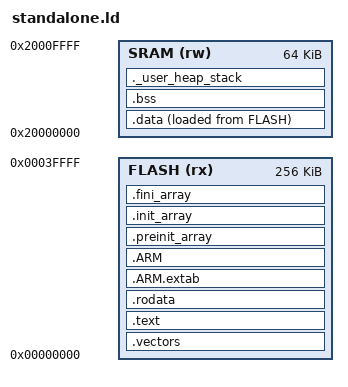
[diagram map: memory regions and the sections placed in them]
/*
******************************************************************************
**
**  File        : LinkerScript.ld
**
**  Author      : STM32CubeIDE
**
**  Abstract    : Linker script for STM32H7 series
**                2048Kbytes FLASH and 1056Kbytes RAM
**
**                Set heap size, stack size and stack location according
**                to application requirements.
**
**                Set memory bank area and size if external memory is used.
**
**  Target      : STMicroelectronics STM32
**
**  Distribution: The file is distributed as is, without any warranty
**                of any kind.
**
*****************************************************************************
** @attention
**
** <h2><center>&copy; Copyright (c) 2021 STMicroelectronics.
** All rights reserved.</center></h2>
**
** This software component is licensed by ST under BSD 3-Clause license,
** the "License"; You may not use this file except in compliance with the
** License. You may obtain a copy of the License at:
**                        opensource.org/licenses/BSD-3-Clause
**
****************************************************************************
*/

/* Highest address of the user mode stack */
_estack = ORIGIN(SRAM) + LENGTH(SRAM);    /* end of RAM */
/* Generate a link error if heap and stack don't fit into RAM */
_Min_Heap_Size = 0x4000 ;      /* required amount of heap  */
_Min_Stack_Size = 0x1000 ; /* required amount of stack */

MEMORY
{
    FLASH (rx) : ORIGIN = 0x00000000, LENGTH = 256K
    SRAM (rw) : ORIGIN = 0x20000000, LENGTH = 64K
}

ENTRY(Reset_Handler)

/* Define output sections */
SECTIONS
{
    /* The startup code goes first into FLASH */
    .vectors :
    {
        . = ALIGN(4);
        KEEP(*(.vectors)) /* Startup code */
        . = ALIGN(4);
    } >FLASH

    /* The program code and other data goes into FLASH */
    .text :
    {
        . = ALIGN(4);
        *(.text)           /* .text sections (code) */
        *(.text*)          /* .text* sections (code) */
        *(.glue_7)         /* glue arm to thumb code */
        *(.glue_7t)        /* glue thumb to arm code */
        *(.eh_frame)

        KEEP (*(.init))
        KEEP (*(.fini))

        . = ALIGN(4);
        __etext = .;        /* define a global symbols at end of code */
    } >FLASH

    /* Constant data goes into FLASH */
    .rodata :
    {
        . = ALIGN(4);
        *(.rodata)         /* .rodata sections (constants, strings, etc.) */
        *(.rodata*)        /* .rodata* sections (constants, strings, etc.) */
        . = ALIGN(4);
    } >FLASH

    .ARM.extab   : { *(.ARM.extab* .gnu.linkonce.armextab.*) } >FLASH
    .ARM : {
        __exidx_start = .;
        *(.ARM.exidx*)
        __exidx_end = .;
    } >FLASH

    .preinit_array     :
    {
        PROVIDE_HIDDEN (__preinit_array_start = .);
        KEEP (*(.preinit_array*))
        PROVIDE_HIDDEN (__preinit_array_end = .);
    } >FLASH

    .init_array :
    {
        PROVIDE_HIDDEN (__init_array_start = .);
        KEEP (*(SORT(.init_array.*)))
        KEEP (*(.init_array*))
        PROVIDE_HIDDEN (__init_array_end = .);
    } >FLASH

    .fini_array :
    {
        PROVIDE_HIDDEN (__fini_array_start = .);
        KEEP (*(SORT(.fini_array.*)))
        KEEP (*(.fini_array*))
        PROVIDE_HIDDEN (__fini_array_end = .);
    } >FLASH

    /* used by the startup to initialize data */
    _sidata = LOADADDR(.data);

    /* Initialized data sections goes into RAM, load LMA copy after code */
    .data :
    {
        . = ALIGN(4);
        __sdata = .;        /* create a global symbol at data start */
        *(.data)           /* .data sections */
        *(.data*)          /* .data* sections */
        *(.RamFunc)        /* .RamFunc sections */
        *(.RamFunc*)       /* .RamFunc* sections */

        . = ALIGN(4);
        __edata = .;        /* define a global symbol at data end */
    } >SRAM AT> FLASH

    /* Uninitialized data section */
    . = ALIGN(4);
    .bss :
    {
        /* This is used by the startup in order to initialize the .bss secion */
        __sbss = .;         /* define a global symbol at bss start */
        __bss_start__ = __sbss;
        *(.bss)
        *(.bss*)
        *(COMMON)

        . = ALIGN(4);
        __ebss = .;         /* define a global symbol at bss end */
        __bss_end__ = __ebss;
    } >SRAM

    /* User_heap_stack section, used to check that there is enough RAM left */
    ._user_heap_stack :
    {
        . = ALIGN(8);
        PROVIDE ( end = . );
        PROVIDE ( _end = . );
        PROVIDE ( __end__ = . );
        . = . + _Min_Heap_Size;
        . = . + _Min_Stack_Size;
        . = ALIGN(8);
    } >SRAM

    /* Remove information from the standard libraries */
    /DISCARD/ :
    {
        libc.a ( * )
        libm.a ( * )
        libgcc.a ( * )
    }

    .ARM.attributes 0 : { *(.ARM.attributes) }
}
